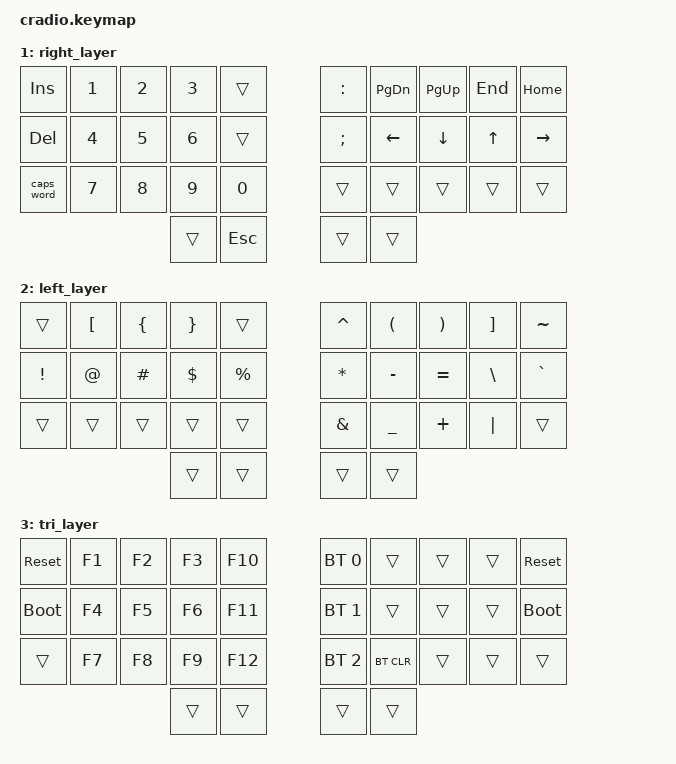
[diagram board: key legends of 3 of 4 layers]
// Copyright (c) 2022 The ZMK Contributors
// SPDX-License-Identifier: MIT

#include <behaviors.dtsi>
#include <dt-bindings/zmk/keys.h>
#include <dt-bindings/zmk/bt.h>

// Home row mods macro
#define HRML(k1,k2,k3,k4) &ht LSHFT k1  &ht LCTRL k2  &ht LGUI k3  &ht LALT k4
#define HRMR(k1,k2,k3,k4) &ht RALT k1  &ht RGUI k2  &ht RCTRL k3  &ht RSHFT k4

/ {
    behaviors {
        ht: hold_tap {
            compatible = "zmk,behavior-hold-tap";
            #binding-cells = <2>;
            flavor = "tap-preferred";
            tapping-term-ms = <220>;
            quick-tap-ms = <150>;
            require-prior-idle-ms = <100>;
            bindings = <&kp>, <&kp>;
        };
    };

    conditional_layers {
        compatible = "zmk,conditional-layers";
        tri_layer {
            if-layers = <1 2>;
            then-layer = <3>;
        };
    };

    keymap {
        compatible = "zmk,keymap";
        default_layer {
            bindings = <
        //╭──────────┬──────────┬──────────┬──────────┬──────────╮   ╭──────────┬──────────┬──────────┬──────────┬──────────╮
        //│  Q       │  W       │  E       │  R       │  T       │   │  Y       │  U       │  I       │  O       │  P       │
            &kp Q      &kp W      &kp E      &kp R      &kp T          &kp Y      &kp U      &kp I      &kp O      &kp P
        //├──────────┼──────────┼──────────┼──────────┼──────────┤   ├──────────┼──────────┼──────────┼──────────┼──────────┤
        //│  A       │  S       │  D       │  F       │  G       │   │  H       │  J       │  K       │  L       │ ' "      │
            HRML(A,        S,         D,         F)     &kp G          &kp H      HRMR(J,        K,         L,        SQT)
        //├──────────┼──────────┼──────────┼──────────┼──────────┤   ├──────────┼──────────┼──────────┼──────────┼──────────┤
        //│  Z       │  X       │  C       │  V       │  B       │   │  N       │  M       │ , <      │ . >      │ / ?      │
            &kp Z      &kp X      &kp C      &kp V      &kp B          &kp N      &kp M      &kp COMMA  &kp DOT    &kp FSLH
        //╰──────────┴──────────┴──────────┼──────────┼──────────┤   ├──────────┼──────────┼──────────┴──────────┴──────────╯
                                            &lt 2 TAB   &kp ENTER     &kp SPACE  &lt 1 BSPC
        //                                 ╰──────────┴──────────╯   ╰──────────┴──────────╯
            >;
        };

        right_layer {
            bindings = <
        //╭──────────┬──────────┬──────────┬──────────┬──────────╮   ╭──────────┬──────────┬──────────┬──────────┬──────────╮
        //│ INSERT   │  1       │  2       │  3       │          │   │ :        │ PAGE DN  │ PAGE UP  │ END      │  :       │
            &kp INS    &kp N1     &kp N2     &kp N3     &trans         &kp COLON  &kp PG_DN  &kp PG_UP  &kp END    &kp HOME
        //├──────────┼──────────┼──────────┼──────────┼──────────┤   ├──────────┼──────────┼──────────┼──────────┼──────────┤
        //│ DELETE   │  4       │  5       │  6       │          │   │ ;        │ LEFT     │ DOWN     │ UP       │  RIGHT   │
            &kp DEL    &kp N4     &kp N5     &kp N6     &trans         &kp SEMI   &kp LEFT   &kp DOWN   &kp UP     &kp RIGHT
        //├──────────┼──────────┼──────────┼──────────┼──────────┤   ├──────────┼──────────┼──────────┼──────────┼──────────┤
        //│ CAPS     │  7       │  8       │  9       │  0       │   │          │          │          │          │          │
           &caps_word  &kp N7     &kp N8     &kp N9     &kp N0         &trans     &trans     &trans     &trans     &trans
        //╰──────────┴──────────┴──────────┼──────────┼──────────┤   ├──────────┼──────────┼──────────┴──────────┴──────────╯
                                             &trans     &kp ESC        &trans     &trans
        //                                 ╰──────────┴──────────╯   ╰──────────┴──────────╯
            >;
        };

        left_layer {
            bindings = <
        //╭──────────┬──────────┬──────────┬──────────┬──────────╮   ╭──────────┬──────────┬──────────┬──────────┬──────────╮
        //│          │  [       │  {       │  }       │          │   │  ^       │  (       │  )       │  ]       │  ~       │
            &trans     &kp LBKT   &kp LBRC   &kp RBRC   &trans         &kp CARET  &kp LPAR   &kp RPAR   &kp RBKT   &kp TILDE
        //├──────────┼──────────┼──────────┼──────────┼──────────┤   ├──────────┼──────────┼──────────┼──────────┼──────────┤
        //│  !       │  @       │  #       │  $       │  %       │   │  *       │  -       │  =       │  \       │  `       │
            &kp EXCL   &kp AT     &kp HASH   &kp DLLR   &kp PRCNT      &kp ASTRK  &kp MINUS  &kp EQUAL  &kp BSLH   &kp GRAVE
        //├──────────┼──────────┼──────────┼──────────┼──────────┤   ├──────────┼──────────┼──────────┼──────────┼──────────┤
        //│          │          │          │          │          │   │  &       │  _       │  +       │  │       │          │
            &trans     &trans     &trans     &trans     &trans         &kp AMPS   &kp UNDER  &kp PLUS   &kp PIPE   &trans
        //╰──────────┴──────────┴──────────┼──────────┼──────────┤   ├──────────┼──────────┼──────────┴──────────┴──────────╯
                                             &trans     &trans         &trans     &trans
        //                                 ╰──────────┴──────────╯   ╰──────────┴──────────╯
            >;
        };

        tri_layer {
            bindings = <
        //╭──────────┬──────────┬──────────┬──────────┬──────────╮   ╭──────────┬──────────┬──────────┬──────────┬──────────╮
        //│ RESET    │          │          │          │          │   │ PROFILE 0│          │          │          │  RESET   │
           &sys_reset  &kp F1     &kp F2     &kp F3     &kp F10        &bt BT_SEL 0 &trans     &trans   &trans    &sys_reset
        //├──────────┼──────────┼──────────┼──────────┼──────────┤   ├──────────┼──────────┼──────────┼──────────┼──────────┤
        //│BOOTLOADER│          │          │          │          │   │ PROFILE 1│          │          │          │BOOTLOADER│
          &bootloader  &kp F4     &kp F5     &kp F6     &kp F11        &bt BT_SEL 1 &trans     &trans   &trans    &bootloader
        //├──────────┼──────────┼──────────┼──────────┼──────────┤   ├──────────┼──────────┼──────────┼──────────┼──────────┤
        //│          │          │          │          │          │   │ PROFILE 2│          │          │          │          │
            &trans     &kp F7     &kp F8     &kp F9     &kp F12        &bt BT_SEL 2 &bt BT_CLR &trans   &trans     &trans
        //╰──────────┴──────────┴──────────┼──────────┼──────────┤   ├──────────┼──────────┼──────────┴──────────┴──────────╯
                                             &trans     &trans         &trans     &trans
        //                                 ╰──────────┴──────────╯   ╰──────────┴──────────╯
            >;
        };
    };
};
